# ZB32L030 register map
Vendor: ZBit.; Series: ZB32L03X; File version: 1.0
CPU: CM0+ r1p0, little endian, no MPU, no FPU, VTOR, 2 interrupt priority bits
Registers are 32-bit, read-write, reset 0x0 unless marked. A register's access mark holds for its fields unless they carry their own. Offsets are from the block's base; [hi:lo] are bit positions.

## SPI
Base 0x40000800
Same registers: SPI0 0x40000800, SPI1 0x40000A00
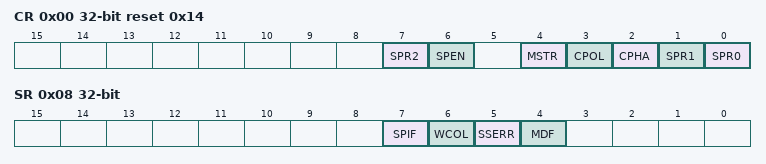
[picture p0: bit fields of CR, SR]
0x00 CR reset 0x14 — SPI Config Register
  [7] SPR2, [6] SPEN, [4] MSTR, [3] CPOL, [2] CPHA, [1] SPR1, [0] SPR0
0x04 SSN — SPI CHIP SELECT CONFIG
  [0] SSN
0x08 SR — SPI Status Register
  [7] SPIF ro, [6] WCOL ro, [5] SSERR ro, [4] MDF ro
0x0C DATA — SPI Data register
  [7:0] SPDATA

## I2C
Base 0x40000C00
Same registers: I2C0 0x40000C00, I2C1 0x40000E00
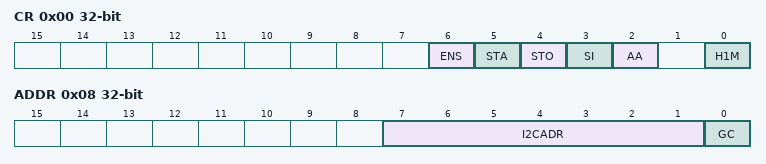
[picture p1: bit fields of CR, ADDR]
0x00 CR — I2C Config Register
  [6] ENS — Enable I2C
  [5] STA — Send Start-bit
  [4] STO — Send Stop-bit
  [3] SI — interrupt flag
  [2] AA — Send Ack
  [0] H1M — Enable High speed 1Mbps
0x04 DATA
  [7:0] I2CDAT — I2C Data
0x08 ADDR — I2C Address Register
  [7:1] I2CADR — I2C Address
  [0] GC — General Call enable
0x0C SR reset 0xF8 — I2C Status register
  [7:0] I2CSTA — I2C status
0x10 TIMRUN — I2C Baund Count Enable
  [0] TME
0x14 BAUDCR — Baud Control Register
  [7:0] TM — Baudrate: SCL = PCLK / (8 * (TM+1))

## LPUART — Low Power UART Register
Base 0x40005000
0x00 SBUF — Data BUFF
  [7:0] SBUF
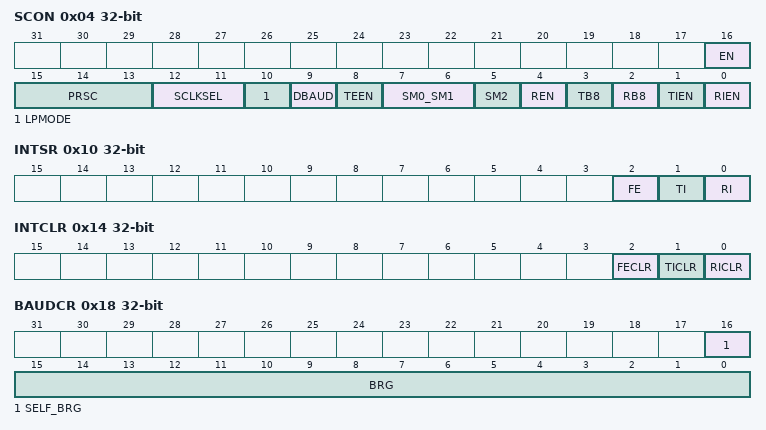
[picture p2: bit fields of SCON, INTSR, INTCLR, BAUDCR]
0x04 SCON — Control Register
  [16] EN — Enable
  [15:13] PRSC
    0=DIV128 (SCLK div128); 1=DIV64 (SCLK div64); 2=DIV32 (SCLK div32); 3=DIV16 (SCLK div16); 4=DIV8 (SCLK div8); 5=DIV4 (SCLK div4); 6=DIV2 (SCLK div2); 7=DIV1 (SCLK div1)
  [12:11] SCLKSEL
    0=PCLK (SCLK is PCLK); 2=LXT (SCLK is LXT); 3=SIRC (SCLK is SIRC)
  [10] LPMODE
  [9] DBAUD
  [8] TEEN
  [7:6] SM0_SM1
    0=MODE_0 (8 Data bits); 1=MODE_1 (8 Data bits, Variable baud rate); 2=MODE_2 (9 Data bits); 3=MODE_3 (9 Data bits, Variable baud rate)
  [5] SM2
  [4] REN
  [3] TB8
  [2] RB8
  [1] TIEN
  [0] RIEN
0x08 SADDR — LPUART Address Register
  [7:0] SADDR
0x0C SADEN — LPUART Address Mask Register
  [7:0] SADEN
0x10 INTSR — LPUART Interrupt flag Status Register
  [2] FE ro, [1] TI ro, [0] RI ro
0x14 INTCLR — LPUART Interruput flag Clear Register
  [2] FECLR wo, [1] TICLR wo, [0] RICLR wo
0x18 BAUDCR — LPUART Baud Control Register
  [16] SELF_BRG, [15:0] BRG

## UART
Base 0x40000000
Same registers: UART0 0x40000000, UART2 0x40000200, UART1 0x40000400, UART3 0x40000600
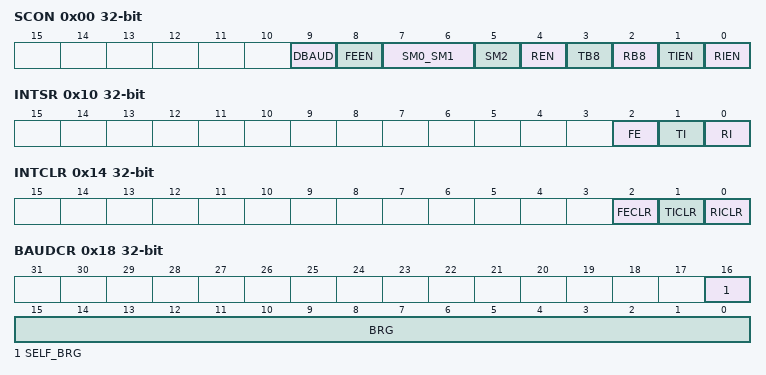
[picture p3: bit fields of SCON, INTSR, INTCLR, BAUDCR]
0x00 SCON — UART Control Register
  [9] DBAUD — Baudrate double
  [8] FEEN — Framing error interrupt enable
  [7:6] SM0_SM1 — UART mode control
    0=MODE_0 (8 Data bits); 1=MODE_1 (8 Data bits, Variable baud rate); 2=MODE_2 (9 Data bits); 3=MODE_3 (9 Data bits, Variable baud rate)
  [5] SM2 — UART multi-communication
  [4] REN — Transmit and Receive Enable
  [3] TB8 — Multi-communication bit
  [2] RB8 — Multi-communication bit
  [1] TIEN — Transmit Interrupt
  [0] RIEN — Receive Interrupt
0x04 SBUF — Data BUFF
  [7:0] SBUF — Data register
0x08 SADDR — Address Register
  [7:0] SADDR — Slave address
0x0C SADEN — Address Mask Register
  [7:0] SADEN — Slave Address Mask
0x10 INTSR — Interrupt flag Status Register
  [2] FE ro, [1] TI ro, [0] RI ro
0x14 INTCLR — UART Interruput flag Clear Register
  [2] FECLR wo, [1] TICLR wo, [0] RICLR wo
0x18 BAUDCR — Baud Control Register
  [16] SELF_BRG — Self Baudrate generate or not
  [15:0] BRG — Baud Rate Generate
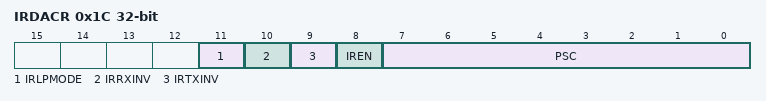
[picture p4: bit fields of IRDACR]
0x1C IRDACR — UART IrDA Control Register
  [11] IRLPMODE — IrDA low-power mode
  [10] IRRXINV — IrDA rx invert data
  [9] IRTXINV — IrDA tx invert data
  [8] IREN — IrDA enable
  [7:0] PSC — IrDA Prescale

## WWDG — Window Watch Dog
Base 0x40002000
0x00 RLOAD reset 0xFF — Count ReLoad Register
  [7:0] RLOAD wo — Reload value
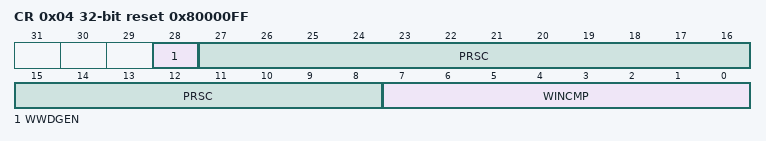
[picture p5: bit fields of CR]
0x04 CR reset 0x80000FF — WWDG Control Register
  [28] WWDGEN — WWDG enable
  [27:8] PRSC — Prescale
  [7:0] WINCMP — WWDG window compare
0x08 INTEN — Interrupt Enable Register
  [0] WWDGIEN — WWDG interrupt enable
0x0C SR — WWDG Interrupt Status Register
  [0] WWDGIF ro — WWDG interrupt flag
0x10 INTCLR — WWDG Interrupt Clear Register
  [0] INTCLR wo — Interrupt flag clear
0x14 CNTVAL reset 0xFF — Count Value
  [7:0] WWDGCNT ro — WWDG count
